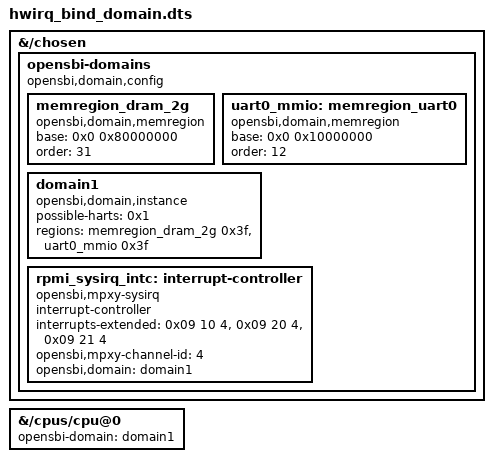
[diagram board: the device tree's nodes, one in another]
/dts-v1/;
/plugin/;

/ {
	/*
	 * Fragment 0: OpenSBI domain configuration under /chosen
	 */
	fragment@0 {
		target-path = "/chosen";
		__overlay__ {
			opensbi-domains {
				compatible = "opensbi,domain,config";

				/*
				 * DRAM region for domain1 (2GB from 0x8000_0000).
				 * base is 64-bit: <hi lo>, order is log2(size).
				 */
				memregion_dram_2g: memregion_dram_2g {
					compatible = "opensbi,domain,memregion";
					base  = <0x0 0x80000000>;
					order = <31>;
				};

				/*
				 * UART MMIO region so S-mode payload can access UART registers
				 * without fault. 0x1000_0000 size 4KB.
				 */
				uart0_mmio: memregion_uart0 {
					compatible = "opensbi,domain,memregion";
					base  = <0x0 0x10000000>;
					order = <12>;
				};

				/*
				 * Domain instance:
				 * - possible-harts = <cpu0 phandle> (cpu@0 phandle is 1)
				 * - regions use label references (fdtoverlay will fixup phandles)
				 * - IRQ routing is defined by sysirq nodes under
				 *   /chosen/opensbi-domains
				 */
				domain1: domain1 {
					compatible = "opensbi,domain,instance";

					/* cpu@0 phandle in base qemu dtb is 1 */
					possible-harts = <0x1>;

					/*
					 * Keep permissive for test.
					 * access=0x3f: enable all M+SU R/W/X flags (test only).
					 */
					regions = <&memregion_dram_2g 0x3f>,
						  <&uart0_mmio 0x3f>;

					/* Route rules are supplied via sysirq nodes. */
				};

				rpmi_sysirq_intc: interrupt-controller {
					compatible = "opensbi,mpxy-sysirq";
					interrupt-controller;
					#interrupt-cells = <1>;

					/*
					 * VIRQ numbers are allocated from zero, in order.
					 * Each entry: <&irqchip hwirq flags>
					 * flags: IRQ_TYPE_LEVEL_HIGH = 4
					 */
					/*
					 * Base DTB (qemu_linux_test.dtb) phandle:
					 * /soc/interrupt-controller@c000000 -> 0x09
					 */
					interrupts-extended =
						<0x09 10 4>, /* VIRQ 0: UART RX */
						<0x09 20 4>, /* VIRQ 1: test */
						<0x09 21 4>; /* VIRQ 2: test */

					/* MPXY channel id allocated by system designer */
					opensbi,mpxy-channel-id = <4>;

					/* Route VIRQs to domain1 */
					opensbi,domain = <&domain1>;
				};
			};
		};
	};

	/*
	 * Fragment 1: Assign cpu0 to domain1 using label reference
	 */
	fragment@1 {
		target-path = "/cpus/cpu@0";
		__overlay__ {
			opensbi-domain = <&domain1>;
		};
	};
};
